# FM33L0XX register map
File version: 1.0
CPU: SC000 r1p0, little endian, no MPU, no FPU, 3 interrupt priority bits
Registers are 32-bit, read-write, reset 0x0 unless marked. A register's access mark holds for its fields unless they carry their own. Offsets are from the block's base; [hi:lo] are bit positions; {n}, {i} and the like mark numbered series; 'fields as' and 'values as' point back to an identical list.

## OPA2 — OPA Registers
Base 0x40012854
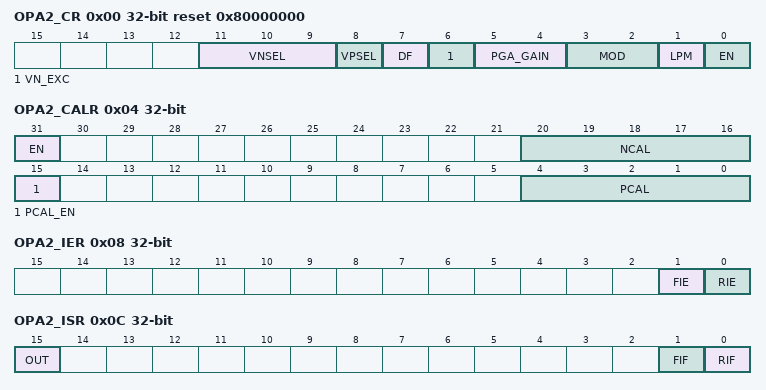
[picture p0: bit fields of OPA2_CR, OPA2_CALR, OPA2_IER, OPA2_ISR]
0x00 OPA2_CR reset 0x80000000 — COMP2 CONTROL REGISTER
  [11:9] VNSEL
    0=OPA1_INN1; 1=OPA1_INN2; 2=VREF; 3=3/4 VREF; 4=1/2 VREF; 5=1/4 VREF; 6=1/8 VREF
  [8] VPSEL
    0=OPA1_INP1; 1=OPA1_INP2
  [7] DF — COMP2DF
    0=DISABLE; 1=ENABLE
  [6] VN_EXC
    0=NOT CONNECT GPIO; 1=CONNECT GPIO
  [5:4] PGA_GAIN
    0=PGA*2; 1=PGA*4; 2=PGA*8; 3=PGA*16
  [3:2] MOD — OPA2MOD
    0=standalone MODE; 1=COMP MODE; 2=PGA MODE; 3=buffer MODE
  [1] LPM — OPA2LPM
    0=NORMAL MODE; 1=LOW POWER MODE
  [0] EN
    0=DISABLE; 1=ENABLE
0x04 OPA2_CALR
  [31] EN — NCAL_EN
    0=DISABLE; 1=ENABLE
  [20:16] NCAL
    0=NOT CHANGE; 1=DECREASE_MIN; 15=DECREASE_MAX; 16=NOT CHANGE; 17=ADD_MIN; 31=ADD_MAX
  [15] PCAL_EN
    0=DISABLE; 1=ENABLE
  [4:0] PCAL
    values as NCAL
0x08 OPA2_IER — COMP IE REGISTER
  [1] FIE — COMP2FIE
    0=DISABLE; 1=ENABLE
  [0] RIE — COMP2RIE
    0=DISABLE; 1=ENABLE
0x0C OPA2_ISR — COMP IF REGISTER
  [15] OUT ro — COMP1O
  [1] FIF — COMP2FIF
    0=DISABLE; 1=ENABLE
  [0] RIF — COMP2RIF
    0=RESET; 1=SET

## LPTIM — LPTIM Registers
Base 0x40013400
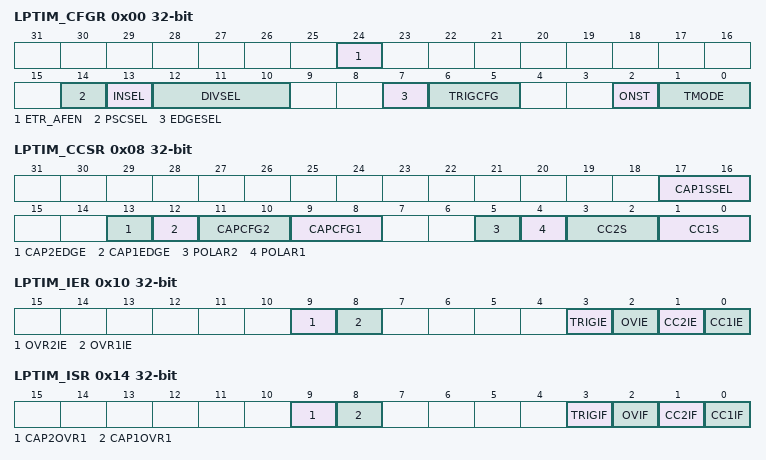
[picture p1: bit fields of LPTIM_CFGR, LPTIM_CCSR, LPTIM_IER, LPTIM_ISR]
0x00 LPTIM_CFGR — LPTIMER CONFIG REGISTER
  [24] ETR_AFEN
    0=DISABLE; 1=ENABLE
  [14] PSCSEL
    0=CLKSEL; 1=LPTINSEL
  [13] INSEL — LPTIM SELECT
    0=PIN INPUT; 1=ADC_EOC
  [12:10] DIVSEL — CLK DIVIDED SELECT
    0=DIV1; 1=DIV2; 2=DIV4; 3=DIV8; 4=DIV16; 5=DIV32; 6=DIV64; 7=DIV128
  [7] EDGESEL — EDGE SELECT
    0=POS; 1=NEG
  [6:5] TRIGCFG
    0=POS; 1=NEG; 2=BOTH; 3=BOTH
  [2] ONST
    0=CONTINUOUS; 1=ONCE
  [1:0] TMODE
    0=OUT_CNT; 1=TRIG_CNT; 2=OUTER_SOURCE; 3=Timeout
0x04 LPTIM_CNT — LPTIMER COUNTER REGISTER
  [31:0] CNT32
0x08 LPTIM_CCSR — LPTIMER COMPARE REGISTER
  [17:16] CAP1SSEL
    0=LPT32_CH1; 1=XTLF; 2=RCLP; 3=RC4M_PSC
  [13] CAP2EDGE
    0=RISING; 1=FALLING
  [12] CAP1EDGE
    0=RISING; 1=FALLING
  [11:10] CAPCFG2
    0=RISING; 1=FALLING; 2=RISING OR FALLING
  [9:8] CAPCFG1
    0=RISING; 1=FALLING; 2=RISING OR FALLING
  [5] POLAR2
    0=POSTIVE; 1=NEGTIVE
  [4] POLAR1
    0=POSTIVE; 1=NEGTIVE
  [3:2] CC2S
    0=DISABLE; 1=LPT32_CH2 CAPTURE; 2=LPT32_CH2 COMPARE; 3=DISABLE
  [1:0] CC1S
    0=DISABLE; 1=LPT32_CH1 CAPTURE; 2=LPT32_CH1 COMPARE; 3=DISABLE
0x0C LPTIM_ARR — LPT_ARR
  [31:0] ARR — LPTARR
0x10 LPTIM_IER — LPTIMER IE REGISTER
  [all] fields
    0=DISABLE; 1=ENABLE
  [9] OVR2IE
  [8] OVR1IE
  [3] TRIGIE
  [2] OVIE
  [1] CC2IE
  [0] CC1IE
0x14 LPTIM_ISR — LPTIMER IF REGISTER
  [all] fields
    0=RESET; 1=SET
  [9] CAP2OVR1
  [8] CAP1OVR1
  [3] TRIGIF
  [2] OVIF
  [1] CC2IF
  [0] CC1IF
0x18 LPTIM_CR — LPTIMER CTRL REGISTER
  [0] EN
0x20 LPTIM_CCR1 — LPT_CCR1
0x24 LPTIM_CCR2 — LPT_CCR2

## AES — AES Registers
Base 0x40013800
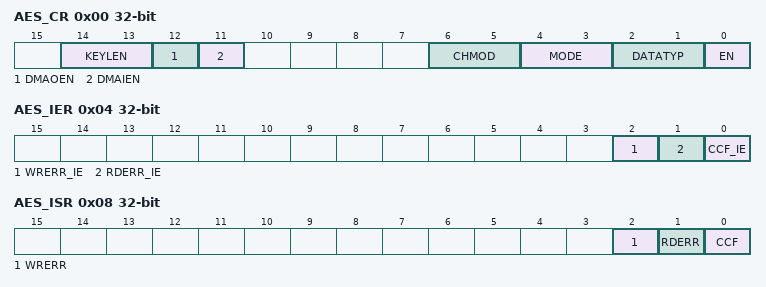
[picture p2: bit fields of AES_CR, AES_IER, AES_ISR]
0x00 AES_CR — AES CONTROL REGISTER
  [14:13] KEYLEN
    0=128bit; 1=192bit; 2=256bit; 3=REV
  [12] DMAOEN
  [11] DMAIEN
  [6:5] CHMOD
    0=ECB; 1=CBC; 2=CTR; 3=MultH
  [4:3] MODE
    0=ENCRYPT; 1=KEY_EXPANSION; 2=DECRYPT; 3=KEYEXP_DEC (KEY_EXPANSION + DECRYPT)
  [2:1] DATATYP
    0=32bit; 1=16bit; 2=8bit; 3=1bit
  [0] EN
0x04 AES_IER — AES IE REGISTER
  [all] fields
    0=DISABLE; 1=ENABLE
  [2] WRERR_IE
  [1] RDERR_IE
  [0] CCF_IE
0x08 AES_ISR — AES IF REGISTER
  [all] fields
    0=RESET; 1=SET
  [2] WRERR
  [1] RDERR
  [0] CCF
0x0C AES_DIR — AES DATA INPUT REGISTER
  [31:0] DIN
0x10 AES_DOR — AES DATA OUTPUT REGISTER
  [31:0] DOUT — AESDOUT
0x14 AES_KEY0
  [31:0] KEY0 — AESKEY
0x18 AES_KEY1
  [31:0] KEY1 — AESKEY
0x1C AES_KEY2
{0x14+4i} AES_KEY{i} (i=3..7)
  [31:0] KEY{i} — AESKEY
{0x34+4i} AES_IVR{i} (i=0..3) — AES INITIAL VECTOR{i} REGISTER
  [31:0] IVR{i} — AESIVR

## RNG_CR — RNG_CR Registers
Base 0x40012864
0x00 RNG_CR — RNG CONFIG REGISTER
  [0] EN — RNG enable
    0=DISABLE; 1=ENABLE

## RNG — TRNG Registers
Base 0x40013C04
0x00 RNG_DOR — RNG OUTPUT REGISTER
  [31:0] OUT
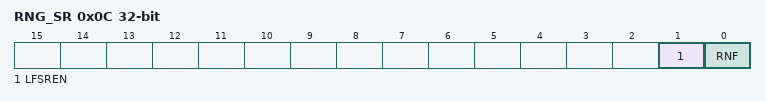
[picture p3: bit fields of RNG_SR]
0x0C RNG_SR — RNG IF REGISTER
  [1] LFSREN ro
    0=RESET; 1=SET
  [0] RNF
    0=RESET; 1=SET
0x10 RNG_CRC_CR
  [0] CRCEN
    0=DISABLE; 1=ENABLE
0x14 RNG_CRC_DIR reset 0xFFFFFFFF
  [31:0] CRCIN
0x18 RNG_CRC_SR
  [0] CRCDONE
    0=RESET; 1=SET

## BSTIM — BASE TIMER Registers
Base 0x40014C00
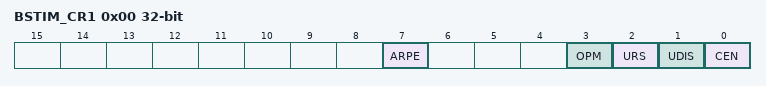
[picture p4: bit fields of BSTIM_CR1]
0x00 BSTIM_CR1 — BSTIMER CONTROL REGISTER1
  [7] ARPE — Auto-reload en
    0=DISABLE; 1=ENABLE
  [3] OPM
    0=counter not stop; 1=counter stop
  [2] URS — update request
    0=update by follows; 1=update inly by overflow
  [1] UDIS
    0=DISABLE; 1=ENABLE
  [0] CEN
    0=DISABLE; 1=ENABLE
0x04 BSIM_CR2 — BSTIMER CONTROL REGISTER 2
  [6:4] MMS — master mode select
    0=UG; 1=CNT_EN; 2=UE
0x0C BSTIM_DIER
  [0] UIE — UPDATE IE
    0=DISABLE; 1=ENABLE
0x10 BSTIM_SR
  [0] UIF
    0=RESET; 1=SET
0x14 BSTIM_EGR
  [0] UG
    0=RESET; 1=SET
0x24 BSTIM_CNT
  [15:0] CNT — COUNT
0x28 BSTIM_PSC
  [15:0] PSC
0x2C BSTIM_ARR
  [15:0] ARR

## ADC — ADC Registers
Base 0x40015000
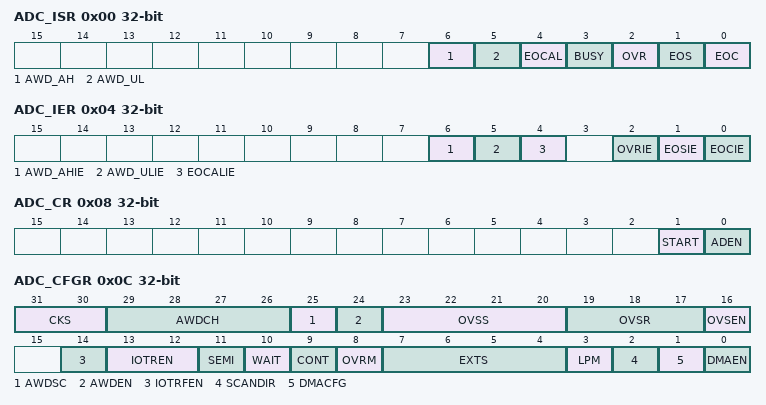
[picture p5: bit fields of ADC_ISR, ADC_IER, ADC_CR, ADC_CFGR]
0x00 ADC_ISR
  [6] AWD_AH
    0=RESET; 1=SET
  [5] AWD_UL
    0=RESET; 1=SET
  [4] EOCAL
    0=RESET; 1=SET
  [3] BUSY ro
    0=counter not stop; 1=counter stop
  [2] OVR
    0=update by follows; 1=update inly by overflow
  [1] EOS
    0=RESET; 1=SET
  [0] EOC
    0=RESET; 1=SET
0x04 ADC_IER
  [all] fields
    0=DISABLE; 1=ENABLE
  [6] AWD_AHIE
  [5] AWD_ULIE
  [4] EOCALIE
  [2] OVRIE
  [1] EOSIE
  [0] EOCIE
0x08 ADC_CR
  [1] START
    0=DISABLE; 1=ENABLE
  [0] ADEN
    0=DISABLE; 1=ENABLE
0x0C ADC_CFGR
  [31:30] CKS
    0=ADCCLK; 1=APBCLK/2; 2=APBCLK/4; 3=APBCLK
  [29:26] AWDCH
  [25] AWDSC
    0=ALL; 1=SINGLE
  [24] AWDEN
    0=DISABLE; 1=ENABLE
  [23:20] OVSS
  [19:17] OVSR
    0=2X; 1=4X; 2=8X; 3=16X; 4=32X; 5=64X; 6=128X; 7=256X
  [16] OVSEN
    0=DISABLE; 1=ENABLE
  [14] IOTRFEN
    0=DISABLE; 1=ENABLE
  [13:12] IOTREN
    0=DISABLE; 1=RISING; 2=FALLING; 3=BOTH
  [11] SEMI — semi-automatic mode en
    0=DISABLE; 1=ENABLE
  [10] WAIT — wait mode en
    0=DISABLE; 1=ENABLE
  [9] CONT — continuous conversion en
    0=DISABLE; 1=ENABLE
  [8] OVRM — overrun mode
    0=maintain; 1=cover
  [7:4] EXTS
  [3] LPM
    0=low power mode; 1=normal mode
  [2] SCANDIR
    0=forward scan; 1=opposite scan
  [1] DMACFG — DMA MODE CFG
    0=single mode; 1=cycle mode
  [0] DMAEN
    0=DISABLE; 1=ENABLE
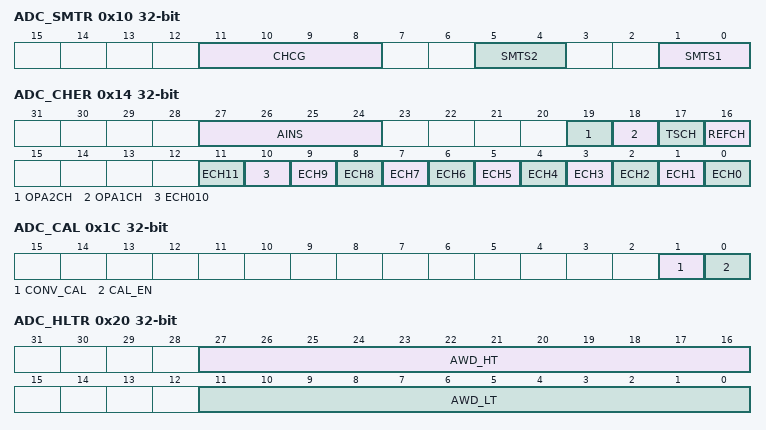
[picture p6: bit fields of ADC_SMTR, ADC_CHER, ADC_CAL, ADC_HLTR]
0x10 ADC_SMTR
  [11:8] CHCG
    0=1; {v}={v} (v=1..10); {v}=10 (v=11..15)
  [5:4] SMTS2
    0=3.5*TMCLK; 1=4.5*TMCLK; 0=6.5*TMCLK; 0=10.5*TMCLK
  [1:0] SMTS1
    0=3.5*TMCLK; 1=4.5*TMCLK; 0=6.5*TMCLK; 0=10.5*TMCLK
0x14 ADC_CHER
  [27:24] AINS
  [19] OPA2CH
    0=DISABLE; 1=ENABLE
  [18] OPA1CH
    0=DISABLE; 1=ENABLE
  [17] TSCH
    0=DISABLE; 1=ENABLE
  [16] REFCH
    0=DISABLE; 1=ENABLE
  [11] ECH11
    0=DISABLE; 1=ENABLE
  [10] ECH010
    0=DISABLE; 1=ENABLE
  [n] ECH{n} (n=0..9)
    0=DISABLE; 1=ENABLE
0x18 ADC_DR
  [15:0] DATA ro
0x1C ADC_CAL
  [1] CONV_CAL
    0=DISABLE; 1=ENABLE
  [0] CAL_EN
    0=DISABLE; 1=ENABLE
0x20 ADC_HLTR
  [27:16] AWD_HT, [11:0] AWD_LT

## BEEPER — BEEPER Registers
Base 0x40015400
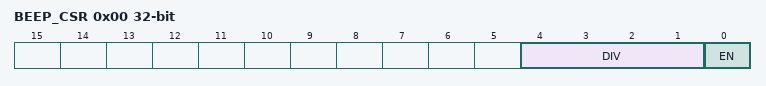
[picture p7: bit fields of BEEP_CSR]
0x00 BEEP_CSR
  [4:1] DIV — BEEPDIV
  [0] EN
    0=DISABLE; 1=ENABLE
